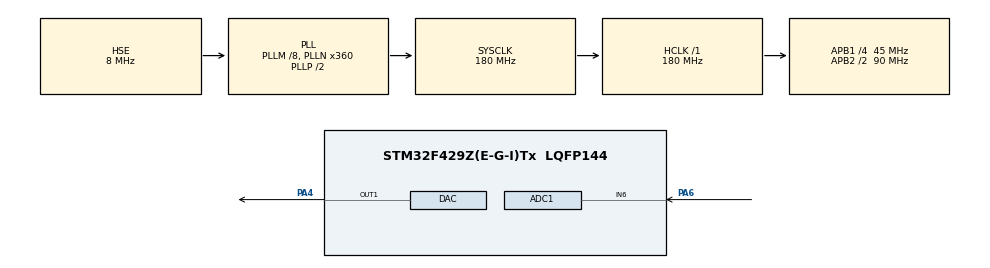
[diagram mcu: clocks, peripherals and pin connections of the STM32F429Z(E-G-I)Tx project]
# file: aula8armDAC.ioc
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ADC1.Channel-0\#ChannelRegularConversion=ADC_CHANNEL_6
ADC1.NbrOfConversionFlag=1
ADC1.Rank-0\#ChannelRegularConversion=1
ADC1.SamplingTime-0\#ChannelRegularConversion=ADC_SAMPLETIME_28CYCLES
ADC1.master=1
DAC.DAC_Trigger=DAC_TRIGGER_T6_TRGO
Dma.DAC1.0.Direction=DMA_MEMORY_TO_PERIPH
Dma.DAC1.0.FIFOMode=DMA_FIFOMODE_DISABLE
Dma.DAC1.0.Instance=DMA1_Stream5
Dma.DAC1.0.MemDataAlignment=DMA_MDATAALIGN_HALFWORD
Dma.DAC1.0.MemInc=DMA_MINC_ENABLE
Dma.DAC1.0.Mode=DMA_CIRCULAR
Dma.DAC1.0.PeriphDataAlignment=DMA_PDATAALIGN_HALFWORD
Dma.DAC1.0.PeriphInc=DMA_PINC_DISABLE
Dma.DAC1.0.Priority=DMA_PRIORITY_LOW
Dma.Request0=DAC1
Mcu.Family=STM32F4
Mcu.Name=STM32F429Z(E-G-I)Tx
Mcu.Package=LQFP144
NVIC.DMA1_Stream5_IRQn=true\:0\:0\:false\:false\:true
NVIC.PriorityGroup=NVIC_PRIORITYGROUP_4
NVIC.TIM6_DAC_IRQn=true\:0\:0\:false\:false\:true
PA13.Mode=Serial_Wire
PA13.Signal=SYS_JTMS-SWDIO
PA14.Mode=Serial_Wire
PA14.Signal=SYS_JTCK-SWCLK
PA4.Signal=COMP_DAC1_group
PA6.Signal=ADCx_IN6
PH0/OSC_IN.Mode=HSE-External-Oscillator
PH0/OSC_IN.Signal=RCC_OSC_IN
PH1/OSC_OUT.Mode=HSE-External-Oscillator
PH1/OSC_OUT.Signal=RCC_OSC_OUT
ProjectManager.HeapSize=0x200
ProjectManager.StackSize=0x400
ProjectManager.TargetToolchain=MDK-ARM V5
RCC.48MHZClocksFreq_Value=90000000
RCC.AHBFreq_Value=180000000
RCC.APB1CLKDivider=RCC_HCLK_DIV4
RCC.APB1Freq_Value=45000000
RCC.APB1TimFreq_Value=90000000
RCC.APB2CLKDivider=RCC_HCLK_DIV2
RCC.APB2Freq_Value=90000000
RCC.APB2TimFreq_Value=180000000
RCC.CortexFreq_Value=180000000
RCC.HCLKFreq_Value=180000000
RCC.HSE_VALUE=8000000
RCC.HSI_VALUE=16000000
RCC.LSE_VALUE=32768
RCC.PLLM=8
RCC.PLLN=360
RCC.PLLSourceVirtual=RCC_PLLSOURCE_HSE
RCC.SYSCLKFreq_VALUE=180000000
RCC.SYSCLKSource=RCC_SYSCLKSOURCE_PLLCLK
RCC.VCOOutputFreq_Value=360000000
SH.ADCx_IN6.0=ADC1_IN6,IN6
SH.COMP_DAC1_group.0=DAC_OUT1,DAC_OUT1
TIM6.Period=1000
TIM6.Prescaler=900
TIM6.TIM_MasterOutputTrigger=TIM_TRGO_UPDATE
VP_TIM6_VS_ClockSourceINT.Mode=Enable_Timer
board=aula8armDAC

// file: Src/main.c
/**
  ******************************************************************************
  * File Name          : main.c
  * Description        : Main program body
  ******************************************************************************
  ** This notice applies to any and all portions of this file
  * that are not between comment pairs USER CODE BEGIN and
  * USER CODE END. Other portions of this file, whether
  * inserted by the user or by software development tools
  * are owned by their respective copyright owners.
  *
  * COPYRIGHT(c) 2017 STMicroelectronics
  *
  * Redistribution and use in source and binary forms, with or without modification,
  * are permitted provided that the following conditions are met:
  *   1. Redistributions of source code must retain the above copyright notice,
  *      this list of conditions and the following disclaimer.
  *   2. Redistributions in binary form must reproduce the above copyright notice,
  *      this list of conditions and the following disclaimer in the documentation
  *      and/or other materials provided with the distribution.
  *   3. Neither the name of STMicroelectronics nor the names of its contributors
  *      may be used to endorse or promote products derived from this software
  *      without specific prior written permission.
  *
  * THIS SOFTWARE IS PROVIDED BY THE COPYRIGHT HOLDERS AND CONTRIBUTORS "AS IS"
  * AND ANY EXPRESS OR IMPLIED WARRANTIES, INCLUDING, BUT NOT LIMITED TO, THE
  * IMPLIED WARRANTIES OF MERCHANTABILITY AND FITNESS FOR A PARTICULAR PURPOSE ARE
  * DISCLAIMED. IN NO EVENT SHALL THE COPYRIGHT HOLDER OR CONTRIBUTORS BE LIABLE
  * FOR ANY DIRECT, INDIRECT, INCIDENTAL, SPECIAL, EXEMPLARY, OR CONSEQUENTIAL
  * DAMAGES (INCLUDING, BUT NOT LIMITED TO, PROCUREMENT OF SUBSTITUTE GOODS OR
  * SERVICES; LOSS OF USE, DATA, OR PROFITS; OR BUSINESS INTERRUPTION) HOWEVER
  * CAUSED AND ON ANY THEORY OF LIABILITY, WHETHER IN CONTRACT, STRICT LIABILITY,
  * OR TORT (INCLUDING NEGLIGENCE OR OTHERWISE) ARISING IN ANY WAY OUT OF THE USE
  * OF THIS SOFTWARE, EVEN IF ADVISED OF THE POSSIBILITY OF SUCH DAMAGE.
  *
  ******************************************************************************
  */
#include "main.h"
#include "stm32f4xx_hal.h"

ADC_HandleTypeDef hadc1;

DAC_HandleTypeDef hdac;
DMA_HandleTypeDef hdma_dac1;

TIM_HandleTypeDef htim6;

/* USER CODE BEGIN PV */
/* Private variables ---------------------------------------------------------*/

uint16_t ecg_samples[170] =
{310,310,350,390,410,390,370,390,430,430,410,410,430,390,370,390,390,370,
	330,320,300,300,300,300,300,300,300,300,320,300,300,300,300,280,300,380,
	600,970,1550,2270,2550,2200,1400,620,70,50,00,90,270,390,370,370,370,350,
	370,370,370,370,390,390,390,410,410,410,410,430,430,450,450,450,450,450,470,
	490,490,490,490,490,490,510,510,530,550,530,550,570,570,590,590,590,610,610,
	630,630,630,650,640,660,660,660,660,660,660,660,660,660,640,620,600,580,540,
	480,460,440,430,410,370,350,350,330,330,330,310,310,310,310,330,330,330,330,
	340,360,360,360,360,360,360,360,360,380,360,360,360,380,360,360,360,360,360,
	340,340,340,340,340,350,330,350,350,330,330,330,330,330,330,330,310,310,310,
	330,310};

int value_adc;
int *address_value_adc; // utilizado para identificar endereço de value_adc

/* USER CODE END PV */

void SystemClock_Config(void);
static void MX_GPIO_Init(void);
static void MX_DMA_Init(void);
static void MX_DAC_Init(void);
static void MX_TIM6_Init(void);
static void MX_ADC1_Init(void);

/* USER CODE BEGIN PFP */
/* Private function prototypes -----------------------------------------------*/

/* USER CODE END PFP */

int main(void)
{

  /* MCU Configuration----------------------------------------------------------*/

  /* Reset of all peripherals, Initializes the Flash interface and the Systick. */
  HAL_Init();

  /* Configure the system clock */
  SystemClock_Config();

  /* Initialize all configured peripherals */
  MX_GPIO_Init();
  MX_DMA_Init();
  MX_DAC_Init();
  MX_TIM6_Init();
  MX_ADC1_Init();

  /* USER CODE BEGIN 2 */

	HAL_TIM_Base_Start(&htim6); // inicia timer
	HAL_DAC_Start(&hdac,DAC_CHANNEL_1); // inicia DAC
	HAL_DAC_Start_DMA(&hdac, DAC_CHANNEL_1, (uint32_t*)ecg_samples, 170, DAC_ALIGN_12B_R); // Passa endereço do vetor de dados para o DMA

  /* USER CODE END 2 */

  /* Infinite loop */
	address_value_adc=&value_adc;
  while (1)
  {

  /* USER CODE BEGIN 3 */
	HAL_ADC_Start(&hadc1);
	HAL_ADC_PollForConversion(&hadc1,10);
	value_adc=HAL_ADC_GetValue(&hadc1);
	HAL_Delay(1);
  }
  /* USER CODE END 3 */

}

/** System Clock Configuration
*/
void SystemClock_Config(void)
{

  RCC_OscInitTypeDef RCC_OscInitStruct;
  RCC_ClkInitTypeDef RCC_ClkInitStruct;

    /**Configure the main internal regulator output voltage
    */
  __HAL_RCC_PWR_CLK_ENABLE();

  __HAL_PWR_VOLTAGESCALING_CONFIG(PWR_REGULATOR_VOLTAGE_SCALE1);

    /**Initializes the CPU, AHB and APB busses clocks
    */
  RCC_OscInitStruct.OscillatorType = RCC_OSCILLATORTYPE_HSE;
  RCC_OscInitStruct.HSEState = RCC_HSE_ON;
  RCC_OscInitStruct.PLL.PLLState = RCC_PLL_ON;
  RCC_OscInitStruct.PLL.PLLSource = RCC_PLLSOURCE_HSE;
  RCC_OscInitStruct.PLL.PLLM = 8;
  RCC_OscInitStruct.PLL.PLLN = 360;
  RCC_OscInitStruct.PLL.PLLP = RCC_PLLP_DIV2;
  RCC_OscInitStruct.PLL.PLLQ = 4;
  if (HAL_RCC_OscConfig(&RCC_OscInitStruct) != HAL_OK)
  {
    _Error_Handler(__FILE__, __LINE__);
  }

    /**Activate the Over-Drive mode
    */
  if (HAL_PWREx_EnableOverDrive() != HAL_OK)
  {
    _Error_Handler(__FILE__, __LINE__);
  }

    /**Initializes the CPU, AHB and APB busses clocks
    */
  RCC_ClkInitStruct.ClockType = RCC_CLOCKTYPE_HCLK|RCC_CLOCKTYPE_SYSCLK
                              |RCC_CLOCKTYPE_PCLK1|RCC_CLOCKTYPE_PCLK2;
  RCC_ClkInitStruct.SYSCLKSource = RCC_SYSCLKSOURCE_PLLCLK;
  RCC_ClkInitStruct.AHBCLKDivider = RCC_SYSCLK_DIV1;
  RCC_ClkInitStruct.APB1CLKDivider = RCC_HCLK_DIV4;
  RCC_ClkInitStruct.APB2CLKDivider = RCC_HCLK_DIV2;

  if (HAL_RCC_ClockConfig(&RCC_ClkInitStruct, FLASH_LATENCY_5) != HAL_OK)
  {
    _Error_Handler(__FILE__, __LINE__);
  }

    /**Configure the Systick interrupt time
    */
  HAL_SYSTICK_Config(HAL_RCC_GetHCLKFreq()/1000);

    /**Configure the Systick
    */
  HAL_SYSTICK_CLKSourceConfig(SYSTICK_CLKSOURCE_HCLK);

  /* SysTick_IRQn interrupt configuration */
  HAL_NVIC_SetPriority(SysTick_IRQn, 0, 0);
}

/* ADC1 init function */
static void MX_ADC1_Init(void)
{

  ADC_ChannelConfTypeDef sConfig;

    /**Configure the global features of the ADC (Clock, Resolution, Data Alignment and number of conversion)
    */
  hadc1.Instance = ADC1;
  hadc1.Init.ClockPrescaler = ADC_CLOCK_SYNC_PCLK_DIV4;
  hadc1.Init.Resolution = ADC_RESOLUTION_12B;
  hadc1.Init.ScanConvMode = DISABLE;
  hadc1.Init.ContinuousConvMode = DISABLE;
  hadc1.Init.DiscontinuousConvMode = DISABLE;
  hadc1.Init.ExternalTrigConvEdge = ADC_EXTERNALTRIGCONVEDGE_NONE;
  hadc1.Init.ExternalTrigConv = ADC_SOFTWARE_START;
  hadc1.Init.DataAlign = ADC_DATAALIGN_RIGHT;
  hadc1.Init.NbrOfConversion = 1;
  hadc1.Init.DMAContinuousRequests = DISABLE;
  hadc1.Init.EOCSelection = ADC_EOC_SINGLE_CONV;
  if (HAL_ADC_Init(&hadc1) != HAL_OK)
  {
    _Error_Handler(__FILE__, __LINE__);
  }

    /**Configure for the selected ADC regular channel its corresponding rank in the sequencer and its sample time.
    */
  sConfig.Channel = ADC_CHANNEL_6;
  sConfig.Rank = 1;
  sConfig.SamplingTime = ADC_SAMPLETIME_28CYCLES;
  if (HAL_ADC_ConfigChannel(&hadc1, &sConfig) != HAL_OK)
  {
    _Error_Handler(__FILE__, __LINE__);
  }

}

/* DAC init function */
static void MX_DAC_Init(void)
{

  DAC_ChannelConfTypeDef sConfig;

    /**DAC Initialization
    */
  hdac.Instance = DAC;
  if (HAL_DAC_Init(&hdac) != HAL_OK)
  {
    _Error_Handler(__FILE__, __LINE__);
  }

    /**DAC channel OUT1 config
    */
  sConfig.DAC_Trigger = DAC_TRIGGER_T6_TRGO;
  sConfig.DAC_OutputBuffer = DAC_OUTPUTBUFFER_ENABLE;
  if (HAL_DAC_ConfigChannel(&hdac, &sConfig, DAC_CHANNEL_1) != HAL_OK)
  {
    _Error_Handler(__FILE__, __LINE__);
  }

}

/* TIM6 init function */
static void MX_TIM6_Init(void)
{

  TIM_MasterConfigTypeDef sMasterConfig;

  htim6.Instance = TIM6;
  htim6.Init.Prescaler = 900;
  htim6.Init.CounterMode = TIM_COUNTERMODE_UP;
  htim6.Init.Period = 1000;
  if (HAL_TIM_Base_Init(&htim6) != HAL_OK)
  {
    _Error_Handler(__FILE__, __LINE__);
  }

  sMasterConfig.MasterOutputTrigger = TIM_TRGO_UPDATE;
  sMasterConfig.MasterSlaveMode = TIM_MASTERSLAVEMODE_DISABLE;
  if (HAL_TIMEx_MasterConfigSynchronization(&htim6, &sMasterConfig) != HAL_OK)
  {
    _Error_Handler(__FILE__, __LINE__);
  }

}

static void MX_DMA_Init(void)
{
  /* DMA controller clock enable */
  __HAL_RCC_DMA1_CLK_ENABLE();

  /* DMA interrupt init */
  /* DMA1_Stream5_IRQn interrupt configuration */
  HAL_NVIC_SetPriority(DMA1_Stream5_IRQn, 0, 0);
  HAL_NVIC_EnableIRQ(DMA1_Stream5_IRQn);

}

/** Configure pins as
        * Analog
        * Input
        * Output
        * EVENT_OUT
        * EXTI
*/
static void MX_GPIO_Init(void)
{

  /* GPIO Ports Clock Enable */
  __HAL_RCC_GPIOH_CLK_ENABLE();
  __HAL_RCC_GPIOA_CLK_ENABLE();

}

void _Error_Handler(char * file, int line)
{
  while(1)
  {
  }
}

/************************ (C) COPYRIGHT STMicroelectronics *****END OF FILE****/
